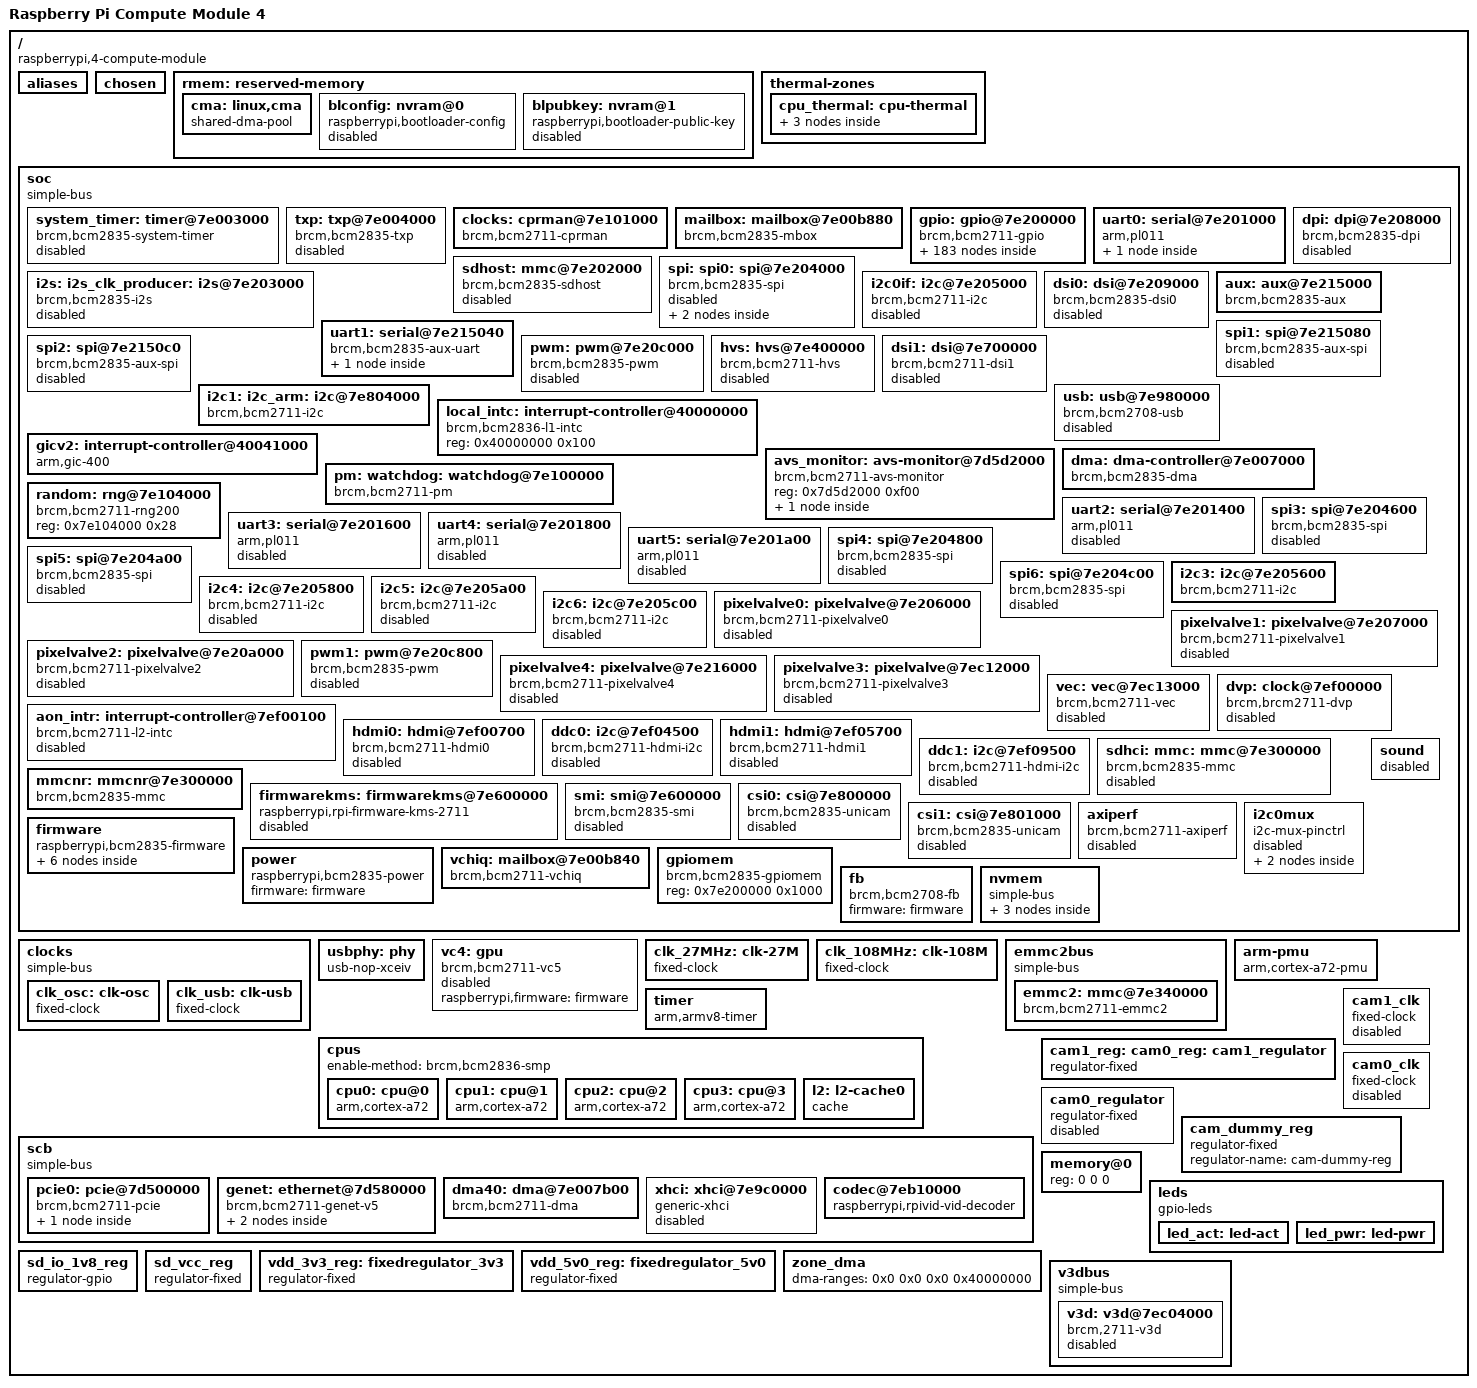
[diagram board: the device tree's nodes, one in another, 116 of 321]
/dts-v1/;

#include <dt-bindings/pinctrl/bcm2835.h>
#include <dt-bindings/clock/bcm2835.h>
#include <dt-bindings/clock/bcm2835-aux.h>
#include <dt-bindings/gpio/gpio.h>
#include <dt-bindings/interrupt-controller/irq.h>
#include <dt-bindings/soc/bcm2835-pm.h>
#include <dt-bindings/interrupt-controller/arm-gic.h>
#include <dt-bindings/power/raspberrypi-power.h>
#include <dt-bindings/reset/raspberrypi,firmware-reset.h>

/memreserve/ 0x00000000 0x00001000;

/ {
	compatible = "raspberrypi,4-compute-module", "brcm,bcm2711";
	model = "Raspberry Pi Compute Module 4";
	#address-cells = <2>;
	#size-cells = <1>;
	interrupt-parent = <&gicv2>;
	aliases: aliases {
		serial0 = &uart1;
		serial1 = &uart0;
		emmc2bus = &emmc2bus;
		ethernet0 = &genet;
		pcie0 = &pcie0;
		blconfig = &blconfig;
		blpubkey = &blpubkey;
		bluetooth = &bt;
		aux = &aux;
		sound = &sound;
		soc = &soc;
		dma = &dma;
		watchdog = &watchdog;
		random = &random;
		mailbox = &mailbox;
		gpio = &gpio;
		uart0 = &uart0;
		uart1 = &uart1;
		sdhost = &sdhost;
		mmc = &mmc;
		mmc1 = &mmcnr;
		mmc0 = &emmc2;
		i2s = &i2s;
		i2c0 = &i2c0;
		i2c1 = &i2c1;
		i2c10 = &i2c_csi_dsi;
		i2c = &i2c1;
		spi0 = &spi0;
		spi1 = &spi1;
		spi2 = &spi2;
		usb = &usb;
		leds = &leds;
		fb = &fb;
		thermal = &thermal;
		axiperf = &axiperf;
		uart2 = &uart2;
		uart3 = &uart3;
		uart4 = &uart4;
		uart5 = &uart5;
		serial2 = &uart2;
		serial3 = &uart3;
		serial4 = &uart4;
		serial5 = &uart5;
		mmc2 = &sdhost;
		i2c3 = &i2c3;
		i2c4 = &i2c4;
		i2c5 = &i2c5;
		i2c6 = &i2c6;
		i2c20 = &ddc0;
		i2c21 = &ddc1;
		spi3 = &spi3;
		spi4 = &spi4;
		spi5 = &spi5;
		spi6 = &spi6;
		i2c_arm = &i2c1;
		i2c_vc = &i2c0;
	};
	chosen: chosen {
		stdout-path = "serial0:115200n8";
		bootargs = "coherent_pool=1M 8250.nr_uarts=1 snd_bcm2835.enable_headphones=0 cgroup_disable=memory numa_policy=interleave";
	};
	rmem: reserved-memory {
		#address-cells = <2>;
		#size-cells = <1>;
		ranges;
		cma: linux,cma {
			compatible = "shared-dma-pool";
			size = <0x4000000>;
			reusable;
			linux,cma-default;
			alloc-ranges = <0x0 0x00000000 0x30000000>;
		};
		blconfig: nvram@0 {
			compatible = "raspberrypi,bootloader-config", "nvmem-rmem";
			#address-cells = <1>;
			#size-cells = <1>;
			reg = <0x0 0x0 0x0>;
			no-map;
			status = "disabled";
		};
		blpubkey: nvram@1 {
			compatible = "raspberrypi,bootloader-public-key", "nvmem-rmem";
			#address-cells = <1>;
			#size-cells = <1>;
			reg = <0x0 0x0 0x0>;
			no-map;
			status = "disabled";
		};
	};
	thermal-zones {
		cpu_thermal: cpu-thermal {
			polling-delay-passive = <0>;
			polling-delay = <1000>;
			coefficients = <(-487) 410040>;
			thermal-sensors = <&thermal>;
			thermal_trips: trips {
				cpu-crit {
					temperature = <110000>;
					hysteresis = <0>;
					type = "critical";
				};
			};
			cooling_maps: cooling-maps {
			};
		};
	};
	soc: soc {
		compatible = "simple-bus";
		#address-cells = <1>;
		#size-cells = <1>;
		ranges = <0x7e000000 0x0 0xfe000000 0x01800000>, <0x7c000000 0x0 0xfc000000 0x02000000>, <0x40000000 0x0 0xff800000 0x00800000>;
		dma-ranges = <0xc0000000 0x0 0x00000000 0x40000000>, <0x7c000000 0x0 0xfc000000 0x03800000>;
		system_timer: timer@7e003000 {
			compatible = "brcm,bcm2835-system-timer";
			reg = <0x7e003000 0x1000>;
			interrupts = <GIC_SPI 64 IRQ_TYPE_LEVEL_HIGH>, <GIC_SPI 65 IRQ_TYPE_LEVEL_HIGH>, <GIC_SPI 66 IRQ_TYPE_LEVEL_HIGH>, <GIC_SPI 67 IRQ_TYPE_LEVEL_HIGH>;
			clock-frequency = <1000000>;
			status = "disabled";
		};
		txp: txp@7e004000 {
			compatible = "brcm,bcm2835-txp";
			reg = <0x7e004000 0x20>;
			interrupts = <GIC_SPI 75 IRQ_TYPE_LEVEL_HIGH>;
			status = "disabled";
		};
		clocks: cprman@7e101000 {
			compatible = "brcm,bcm2711-cprman";
			#clock-cells = <1>;
			reg = <0x7e101000 0x2000>;
			clocks = <&clk_osc>, <&dsi0 0>, <&dsi0 1>, <&dsi0 2>, <&dsi1 0>, <&dsi1 1>, <&dsi1 2>;
			firmware = <&firmware>;
		};
		mailbox: mailbox@7e00b880 {
			compatible = "brcm,bcm2835-mbox";
			reg = <0x7e00b880 0x40>;
			interrupts = <GIC_SPI 33 IRQ_TYPE_LEVEL_HIGH>;
			#mbox-cells = <0>;
		};
		gpio: gpio@7e200000 {
			compatible = "brcm,bcm2711-gpio";
			reg = <0x7e200000 0xb4>;
			interrupts = <GIC_SPI 113 IRQ_TYPE_LEVEL_HIGH>, <GIC_SPI 114 IRQ_TYPE_LEVEL_HIGH>;
			gpio-controller;
			#gpio-cells = <2>;
			interrupt-controller;
			#interrupt-cells = <2>;
			gpio-ranges = <&gpio 0 0 58>;
			gpio-line-names = "ID_SDA", "ID_SCL", "GPIO2", "GPIO3", "GPIO4", "GPIO5", "GPIO6", "GPIO7", "GPIO8", "GPIO9", "GPIO10", "GPIO11", "GPIO12", "GPIO13", "GPIO14", "GPIO15", "GPIO16", "GPIO17", "GPIO18", "GPIO19", "GPIO20", "GPIO21", "GPIO22", "GPIO23", "GPIO24", "GPIO25", "GPIO26", "GPIO27", "RGMII_MDIO", "RGMIO_MDC", "CTS0", "RTS0", "TXD0", "RXD0", "SD1_CLK", "SD1_CMD", "SD1_DATA0", "SD1_DATA1", "SD1_DATA2", "SD1_DATA3", "PWM0_MISO", "PWM1_MOSI", "STATUS_LED_G_CLK", "SPIFLASH_CE_N", "SDA0", "SCL0", "RGMII_RXCLK", "RGMII_RXCTL", "RGMII_RXD0", "RGMII_RXD1", "RGMII_RXD2", "RGMII_RXD3", "RGMII_TXCLK", "RGMII_TXCTL", "RGMII_TXD0", "RGMII_TXD1", "RGMII_TXD2", "RGMII_TXD3";
			dpi_gpio0: dpi-gpio0 {
				brcm,pins = <0 1 2 3 4 5 6 7 8 9 10 11 12 13 14 15 16 17 18 19 20 21 22 23 24 25 26 27>;
				brcm,function = <BCM2835_FSEL_ALT2>;
			};
			emmc_gpio22: emmc-gpio22 {
				brcm,pins = <22 23 24 25 26 27>;
				brcm,function = <BCM2835_FSEL_ALT3>;
			};
			emmc_gpio34: emmc-gpio34 {
				brcm,pins = <34 35 36 37 38 39>;
				brcm,function = <BCM2835_FSEL_ALT3>;
				brcm,pull = <BCM2835_PUD_OFF BCM2835_PUD_UP BCM2835_PUD_UP BCM2835_PUD_UP BCM2835_PUD_UP BCM2835_PUD_UP>;
			};
			emmc_gpio48: emmc-gpio48 {
				brcm,pins = <48 49 50 51 52 53>;
				brcm,function = <BCM2835_FSEL_ALT3>;
			};
			gpclk0_gpio4: gpclk0-gpio4 {
				brcm,pins = <4>;
				brcm,function = <BCM2835_FSEL_ALT0>;
			};
			gpclk1_gpio5: gpclk1-gpio5 {
				brcm,pins = <5>;
				brcm,function = <BCM2835_FSEL_ALT0>;
			};
			gpclk1_gpio42: gpclk1-gpio42 {
				brcm,pins = <42>;
				brcm,function = <BCM2835_FSEL_ALT0>;
			};
			gpclk1_gpio44: gpclk1-gpio44 {
				brcm,pins = <44>;
				brcm,function = <BCM2835_FSEL_ALT0>;
			};
			gpclk2_gpio6: gpclk2-gpio6 {
				brcm,pins = <6>;
				brcm,function = <BCM2835_FSEL_ALT0>;
			};
			gpclk2_gpio43: gpclk2-gpio43 {
				brcm,pins = <43>;
				brcm,function = <BCM2835_FSEL_ALT0>;
				brcm,pull = <BCM2835_PUD_OFF>;
			};
			i2c0_gpio0: i2c0if-gpio0 {
				brcm,pins = <0 1>;
				brcm,function = <BCM2835_FSEL_ALT0>;
			};
			i2c0_gpio28: i2c0if-gpio28 {
				brcm,pins = <28 29>;
				brcm,function = <BCM2835_FSEL_ALT0>;
			};
			i2c0_gpio44: i2c0if-gpio44 {
				brcm,pins = <44 45>;
				brcm,function = <BCM2835_FSEL_ALT1>;
			};
			i2c1_gpio2: i2c1-gpio2 {
				brcm,pins = <2 3>;
				brcm,function = <BCM2835_FSEL_ALT0>;
			};
			i2c1_gpio44: i2c1-gpio44 {
				brcm,pins = <44 45>;
				brcm,function = <BCM2835_FSEL_ALT2>;
			};
			jtag_gpio22: jtag-gpio22 {
				brcm,pins = <22 23 24 25 26 27>;
				brcm,function = <BCM2835_FSEL_ALT4>;
			};
			pcm_gpio18: pcm-gpio18 {
				brcm,pins = <18 19 20 21>;
				brcm,function = <BCM2835_FSEL_ALT0>;
			};
			pcm_gpio28: pcm-gpio28 {
				brcm,pins = <28 29 30 31>;
				brcm,function = <BCM2835_FSEL_ALT2>;
			};
			sdhost_gpio48: sdhost-gpio48 {
				brcm,pins = <48 49 50 51 52 53>;
				brcm,function = <BCM2835_FSEL_ALT0>;
			};
			spi0_gpio7: spi0-gpio7 {
				brcm,pins = <7 8 9 10 11>;
				brcm,function = <BCM2835_FSEL_ALT0>;
			};
			spi0_gpio35: spi0-gpio35 {
				brcm,pins = <35 36 37 38 39>;
				brcm,function = <BCM2835_FSEL_ALT0>;
			};
			spi1_gpio16: spi1-gpio16 {
				brcm,pins = <16 17 18 19 20 21>;
				brcm,function = <BCM2835_FSEL_ALT4>;
			};
			spi2_gpio40: spi2-gpio40 {
				brcm,pins = <40 41 42 43 44 45>;
				brcm,function = <BCM2835_FSEL_ALT4>;
			};
			uart0_gpio14: uart0-gpio14 {
				brcm,pins = <14 15>;
				brcm,function = <BCM2835_FSEL_ALT0>;
			};
			uart0_ctsrts_gpio16: uart0-ctsrts-gpio16 {
				brcm,pins = <16 17>;
				brcm,function = <BCM2835_FSEL_ALT3>;
			};
			uart0_ctsrts_gpio30: uart0-ctsrts-gpio30 {
				brcm,pins = <30 31>;
				brcm,function = <BCM2835_FSEL_ALT3>;
				brcm,pull = <BCM2835_PUD_UP BCM2835_PUD_OFF>;
			};
			uart0_gpio32: uart0-gpio32 {
				brcm,pins = <32 33>;
				brcm,function = <BCM2835_FSEL_ALT3>;
				brcm,pull = <BCM2835_PUD_OFF BCM2835_PUD_UP>;
			};
			uart0_gpio36: uart0-gpio36 {
				brcm,pins = <36 37>;
				brcm,function = <BCM2835_FSEL_ALT2>;
			};
			uart0_ctsrts_gpio38: uart0-ctsrts-gpio38 {
				brcm,pins = <38 39>;
				brcm,function = <BCM2835_FSEL_ALT2>;
			};
			uart1_gpio14: uart1-gpio14 {
				brcm,pins = <14 15>;
				brcm,function = <BCM2835_FSEL_ALT5>;
			};
			uart1_ctsrts_gpio16: uart1-ctsrts-gpio16 {
				brcm,pins = <16 17>;
				brcm,function = <BCM2835_FSEL_ALT5>;
			};
			uart1_gpio32: uart1-gpio32 {
				brcm,pins = <32 33>;
				brcm,function = <BCM2835_FSEL_ALT5>;
			};
			uart1_ctsrts_gpio30: uart1-ctsrts-gpio30 {
				brcm,pins = <30 31>;
				brcm,function = <BCM2835_FSEL_ALT5>;
			};
			uart1_gpio40: uart1-gpio40 {
				brcm,pins = <40 41>;
				brcm,function = <BCM2835_FSEL_ALT5>;
			};
			uart1_ctsrts_gpio42: uart1-ctsrts-gpio42 {
				brcm,pins = <42 43>;
				brcm,function = <BCM2835_FSEL_ALT5>;
			};
			gpclk0_gpio49: gpclk0-gpio49 {
				pin-gpclk {
					pins = "gpio49";
					function = "alt1";
					bias-disable;
				};
			};
			gpclk1_gpio50: gpclk1-gpio50 {
				pin-gpclk {
					pins = "gpio50";
					function = "alt1";
					bias-disable;
				};
			};
			gpclk2_gpio51: gpclk2-gpio51 {
				pin-gpclk {
					pins = "gpio51";
					function = "alt1";
					bias-disable;
				};
			};
			i2c0_gpio46: i2c0if-gpio46 {
				pin-sda {
					function = "alt0";
					pins = "gpio46";
					bias-pull-up;
				};
				pin-scl {
					function = "alt0";
					pins = "gpio47";
					bias-disable;
				};
			};
			i2c1_gpio46: i2c1-gpio46 {
				pin-sda {
					function = "alt1";
					pins = "gpio46";
					bias-pull-up;
				};
				pin-scl {
					function = "alt1";
					pins = "gpio47";
					bias-disable;
				};
			};
			i2c3_gpio2: i2c3-gpio2 {
				pin-sda {
					function = "alt5";
					pins = "gpio2";
					bias-pull-up;
				};
				pin-scl {
					function = "alt5";
					pins = "gpio3";
					bias-disable;
				};
			};
			i2c3_gpio4: i2c3-gpio4 {
				pin-sda {
					function = "alt5";
					pins = "gpio4";
					bias-pull-up;
				};
				pin-scl {
					function = "alt5";
					pins = "gpio5";
					bias-disable;
				};
			};
			i2c4_gpio6: i2c4-gpio6 {
				pin-sda {
					function = "alt5";
					pins = "gpio6";
					bias-pull-up;
				};
				pin-scl {
					function = "alt5";
					pins = "gpio7";
					bias-disable;
				};
			};
			i2c4_gpio8: i2c4-gpio8 {
				pin-sda {
					function = "alt5";
					pins = "gpio8";
					bias-pull-up;
				};
				pin-scl {
					function = "alt5";
					pins = "gpio9";
					bias-disable;
				};
			};
			i2c5_gpio10: i2c5-gpio10 {
				pin-sda {
					function = "alt5";
					pins = "gpio10";
					bias-pull-up;
				};
				pin-scl {
					function = "alt5";
					pins = "gpio11";
					bias-disable;
				};
			};
			i2c5_gpio12: i2c5-gpio12 {
				pin-sda {
					function = "alt5";
					pins = "gpio12";
					bias-pull-up;
				};
				pin-scl {
					function = "alt5";
					pins = "gpio13";
					bias-disable;
				};
			};
			i2c6_gpio0: i2c6-gpio0 {
				pin-sda {
					function = "alt5";
					pins = "gpio0";
					bias-pull-up;
				};
				pin-scl {
					function = "alt5";
					pins = "gpio1";
					bias-disable;
				};
			};
			i2c6_gpio22: i2c6-gpio22 {
				pin-sda {
					function = "alt5";
					pins = "gpio22";
					bias-pull-up;
				};
				pin-scl {
					function = "alt5";
					pins = "gpio23";
					bias-disable;
				};
			};
			i2c_slave_gpio8: i2c-slave-gpio8 {
				pins-i2c-slave {
					pins = "gpio8", "gpio9", "gpio10", "gpio11";
					function = "alt3";
				};
			};
			jtag_gpio48: jtag-gpio48 {
				pins-jtag {
					pins = "gpio48", "gpio49", "gpio50", "gpio51", "gpio52", "gpio53";
					function = "alt4";
				};
			};
			mii_gpio28: mii-gpio28 {
				pins-mii {
					pins = "gpio28", "gpio29", "gpio30", "gpio31";
					function = "alt4";
				};
			};
			mii_gpio36: mii-gpio36 {
				pins-mii {
					pins = "gpio36", "gpio37", "gpio38", "gpio39";
					function = "alt5";
				};
			};
			pcm_gpio50: pcm-gpio50 {
				pins-pcm {
					pins = "gpio50", "gpio51", "gpio52", "gpio53";
					function = "alt2";
				};
			};
			pwm0_0_gpio12: pwm0-0-gpio12 {
				pin-pwm {
					pins = "gpio12";
					function = "alt0";
					bias-disable;
				};
			};
			pwm0_0_gpio18: pwm0-0-gpio18 {
				pin-pwm {
					pins = "gpio18";
					function = "alt5";
					bias-disable;
				};
			};
			pwm1_0_gpio40: pwm1-0-gpio40 {
				pin-pwm {
					pins = "gpio40";
					function = "alt0";
					bias-disable;
				};
			};
			pwm0_1_gpio13: pwm0-1-gpio13 {
				pin-pwm {
					pins = "gpio13";
					function = "alt0";
					bias-disable;
				};
			};
			pwm0_1_gpio19: pwm0-1-gpio19 {
				pin-pwm {
					pins = "gpio19";
					function = "alt5";
					bias-disable;
				};
			};
			pwm1_1_gpio41: pwm1-1-gpio41 {
				pin-pwm {
					pins = "gpio41";
					function = "alt0";
					bias-disable;
				};
			};
			pwm0_1_gpio45: pwm0-1-gpio45 {
				pin-pwm {
					pins = "gpio45";
					function = "alt0";
					bias-disable;
				};
			};
			pwm0_0_gpio52: pwm0-0-gpio52 {
				pin-pwm {
					pins = "gpio52";
					function = "alt1";
					bias-disable;
				};
			};
			pwm0_1_gpio53: pwm0-1-gpio53 {
				pin-pwm {
					pins = "gpio53";
					function = "alt1";
					bias-disable;
				};
			};
			rgmii_gpio35: rgmii-gpio35 {
				pin-start-stop {
					pins = "gpio35";
					function = "alt4";
				};
				pin-rx-ok {
					pins = "gpio36";
					function = "alt4";
				};
			};
			rgmii_irq_gpio34: rgmii-irq-gpio34 {
				pin-irq {
					pins = "gpio34";
					function = "alt5";
				};
			};
			rgmii_irq_gpio39: rgmii-irq-gpio39 {
				pin-irq {
					pins = "gpio39";
					function = "alt4";
				};
			};
			rgmii_mdio_gpio28: rgmii-mdio-gpio28 {
				pins-mdio {
					pins = "gpio28", "gpio29";
					function = "alt5";
				};
			};
			rgmii_mdio_gpio37: rgmii-mdio-gpio37 {
				pins-mdio {
					pins = "gpio37", "gpio38";
					function = "alt4";
				};
			};
			spi0_gpio46: spi0-gpio46 {
				pins-spi {
					pins = "gpio46", "gpio47", "gpio48", "gpio49";
					function = "alt2";
				};
			};
			spi2_gpio46: spi2-gpio46 {
				pins-spi {
					pins = "gpio46", "gpio47", "gpio48", "gpio49", "gpio50";
					function = "alt5";
				};
			};
			spi3_gpio0: spi3-gpio0 {
				pins-spi {
					pins = "gpio0", "gpio1", "gpio2", "gpio3";
					function = "alt3";
				};
			};
			spi4_gpio4: spi4-gpio4 {
				pins-spi {
					pins = "gpio4", "gpio5", "gpio6", "gpio7";
					function = "alt3";
				};
			};
			spi5_gpio12: spi5-gpio12 {
				pins-spi {
					pins = "gpio12", "gpio13", "gpio14", "gpio15";
					function = "alt3";
				};
			};
			spi6_gpio18: spi6-gpio18 {
				pins-spi {
					pins = "gpio18", "gpio19", "gpio20", "gpio21";
					function = "alt3";
				};
			};
			uart2_gpio0: uart2-gpio0 {
				pin-tx {
					pins = "gpio0";
					function = "alt4";
					bias-disable;
				};
				pin-rx {
					pins = "gpio1";
					function = "alt4";
					bias-pull-up;
				};
			};
			uart2_ctsrts_gpio2: uart2-ctsrts-gpio2 {
				pin-cts {
					pins = "gpio2";
					function = "alt4";
					bias-pull-up;
				};
				pin-rts {
					pins = "gpio3";
					function = "alt4";
					bias-disable;
				};
			};
			uart3_gpio4: uart3-gpio4 {
				pin-tx {
					pins = "gpio4";
					function = "alt4";
					bias-disable;
				};
				pin-rx {
					pins = "gpio5";
					function = "alt4";
					bias-pull-up;
				};
			};
			uart3_ctsrts_gpio6: uart3-ctsrts-gpio6 {
				pin-cts {
					pins = "gpio6";
					function = "alt4";
					bias-pull-up;
				};
				pin-rts {
					pins = "gpio7";
					function = "alt4";
					bias-disable;
				};
			};
			uart4_gpio8: uart4-gpio8 {
				pin-tx {
					pins = "gpio8";
					function = "alt4";
					bias-disable;
				};
				pin-rx {
					pins = "gpio9";
					function = "alt4";
					bias-pull-up;
				};
			};
			uart4_ctsrts_gpio10: uart4-ctsrts-gpio10 {
				pin-cts {
					pins = "gpio10";
					function = "alt4";
					bias-pull-up;
				};
				pin-rts {
					pins = "gpio11";
					function = "alt4";
					bias-disable;
				};
			};
			uart5_gpio12: uart5-gpio12 {
				pin-tx {
					pins = "gpio12";
					function = "alt4";
					bias-disable;
				};
				pin-rx {
					pins = "gpio13";
					function = "alt4";
					bias-pull-up;
				};
			};
			uart5_ctsrts_gpio14: uart5-ctsrts-gpio14 {
				pin-cts {
					pins = "gpio14";
					function = "alt4";
					bias-pull-up;
				};
				pin-rts {
					pins = "gpio15";
					function = "alt4";
					bias-disable;
				};
			};
			dpi_18bit_cpadhi_gpio0: dpi_18bit_cpadhi_gpio0 {
				brcm,pins = <0 1 2 3 4 5 6 7 8 9 12 13 14 15 16 17 20 21 22 23 24 25>;
				brcm,function = <BCM2835_FSEL_ALT2>;
				brcm,pull = <0>;
			};
			dpi_18bit_cpadhi_gpio2: dpi_18bit_cpadhi_gpio2 {
				brcm,pins = <2 3 4 5 6 7 8 9 12 13 14 15 16 17 20 21 22 23 24 25>;
				brcm,function = <BCM2835_FSEL_ALT2>;
			};
			dpi_18bit_gpio0: dpi_18bit_gpio0 {
				brcm,pins = <0 1 2 3 4 5 6 7 8 9 10 11 12 13 14 15 16 17 18 19 20 21>;
				brcm,function = <BCM2835_FSEL_ALT2>;
			};
			dpi_18bit_gpio2: dpi_18bit_gpio2 {
				brcm,pins = <2 3 4 5 6 7 8 9 10 11 12 13 14 15 16 17 18 19 20 21>;
				brcm,function = <BCM2835_FSEL_ALT2>;
			};
			dpi_16bit_gpio0: dpi_16bit_gpio0 {
				brcm,pins = <0 1 2 3 4 5 6 7 8 9 10 11 12 13 14 15 16 17 18 19>;
				brcm,function = <BCM2835_FSEL_ALT2>;
			};
			dpi_16bit_gpio2: dpi_16bit_gpio2 {
				brcm,pins = <2 3 4 5 6 7 8 9 10 11 12 13 14 15 16 17 18 19>;
				brcm,function = <BCM2835_FSEL_ALT2>;
			};
			dpi_16bit_cpadhi_gpio0: dpi_16bit_cpadhi_gpio0 {
				brcm,pins = <0 1 2 3 4 5 6 7 8 12 13 14 15 16 17 20 21 22 23 24>;
				brcm,function = <BCM2835_FSEL_ALT2>;
			};
			dpi_16bit_cpadhi_gpio2: dpi_16bit_cpadhi_gpio2 {
				brcm,pins = <2 3 4 5 6 7 8 12 13 14 15 16 17 20 21 22 23 24>;
				brcm,function = <BCM2835_FSEL_ALT2>;
			};
			gpioout: gpioout {
				brcm,pins = <6>;
				brcm,function = <BCM2835_FSEL_GPIO_OUT>;
			};
			alt0: alt0 {
				brcm,pins = <4 5 7 8 9 10 11>;
				brcm,function = <BCM2835_FSEL_ALT0>;
			};
			spi0_pins: spi0_pins {
				brcm,pins = <9 10 11>;
				brcm,function = <BCM2835_FSEL_ALT0>;
			};
			spi0_cs_pins: spi0_cs_pins {
				brcm,pins = <8 7>;
				brcm,function = <BCM2835_FSEL_GPIO_OUT>;
			};
			spi3_pins: spi3_pins {
				brcm,pins = <1 2 3>;
				brcm,function = <BCM2835_FSEL_ALT3>;
			};
			spi3_cs_pins: spi3_cs_pins {
				brcm,pins = <0 24>;
				brcm,function = <BCM2835_FSEL_GPIO_OUT>;
			};
			spi4_pins: spi4_pins {
				brcm,pins = <5 6 7>;
				brcm,function = <BCM2835_FSEL_ALT3>;
			};
			spi4_cs_pins: spi4_cs_pins {
				brcm,pins = <4 25>;
				brcm,function = <BCM2835_FSEL_GPIO_OUT>;
			};
			spi5_pins: spi5_pins {
				brcm,pins = <13 14 15>;
				brcm,function = <BCM2835_FSEL_ALT3>;
			};
			spi5_cs_pins: spi5_cs_pins {
				brcm,pins = <12 26>;
				brcm,function = <BCM2835_FSEL_GPIO_OUT>;
			};
			spi6_pins: spi6_pins {
				brcm,pins = <19 20 21>;
				brcm,function = <BCM2835_FSEL_ALT3>;
			};
			spi6_cs_pins: spi6_cs_pins {
				brcm,pins = <18 27>;
				brcm,function = <BCM2835_FSEL_GPIO_OUT>;
			};
			i2c0_pins: i2c0 {
				brcm,pins = <0 1>;
				brcm,function = <BCM2835_FSEL_ALT0>;
				brcm,pull = <BCM2835_PUD_UP>;
			};
			i2c1_pins: i2c1 {
				brcm,pins = <2 3>;
				brcm,function = <BCM2835_FSEL_ALT0>;
				brcm,pull = <BCM2835_PUD_UP>;
			};
			i2c3_pins: i2c3 {
				brcm,pins = <4 5>;
				brcm,function = <BCM2835_FSEL_ALT5>;
				brcm,pull = <BCM2835_PUD_UP>;
			};
			i2c4_pins: i2c4 {
				brcm,pins = <8 9>;
				brcm,function = <BCM2835_FSEL_ALT5>;
				brcm,pull = <BCM2835_PUD_UP>;
			};
			i2c5_pins: i2c5 {
				brcm,pins = <12 13>;
				brcm,function = <BCM2835_FSEL_ALT5>;
				brcm,pull = <BCM2835_PUD_UP>;
			};
			i2c6_pins: i2c6 {
				brcm,pins = <22 23>;
				brcm,function = <BCM2835_FSEL_ALT5>;
				brcm,pull = <BCM2835_PUD_UP>;
			};
			i2s_pins: i2s {
				brcm,pins = <18 19 20 21>;
				brcm,function = <BCM2835_FSEL_ALT0>;
			};
			sdio_pins: sdio_pins {
				brcm,pins = <34 35 36 37 38 39>;
				brcm,function = <BCM2835_FSEL_ALT3>;
				brcm,pull = <0 2 2 2 2 2>;
			};
			uart2_pins: uart2_pins {
				brcm,pins = <0 1>;
				brcm,function = <BCM2835_FSEL_ALT4>;
				brcm,pull = <0 2>;
			};
			uart3_pins: uart3_pins {
				brcm,pins = <4 5>;
				brcm,function = <BCM2835_FSEL_ALT4>;
				brcm,pull = <0 2>;
			};
			uart4_pins: uart4_pins {
				brcm,pins = <8 9>;
				brcm,function = <BCM2835_FSEL_ALT4>;
				brcm,pull = <0 2>;
			};
			uart5_pins: uart5_pins {
				brcm,pins = <12 13>;
				brcm,function = <BCM2835_FSEL_ALT4>;
				brcm,pull = <0 2>;
			};
			bt_pins: bt_pins {
				brcm,pins = "-";
				brcm,function = <0>;
				brcm,pull = <2>;
			};
			uart0_pins: uart0_pins {
				brcm,pins = <32 33>;
				brcm,function = <BCM2835_FSEL_ALT3>;
				brcm,pull = <0 2>;
			};
			uart1_pins: uart1_pins {
				brcm,pins;
				brcm,function;
				brcm,pull;
			};
			uart1_bt_pins: uart1_bt_pins {
				brcm,pins = <32 33 30 31>;
				brcm,function = <BCM2835_FSEL_ALT5>;
				brcm,pull = <0 2 2 0>;
			};
			audio_pins: audio_pins {
				brcm,pins = <>;
				brcm,function = <>;
			};
		};
		uart0: serial@7e201000 {
			compatible = "arm,pl011", "arm,primecell";
			reg = <0x7e201000 0x200>;
			interrupts = <GIC_SPI 121 IRQ_TYPE_LEVEL_HIGH>;
			clocks = <&clocks BCM2835_CLOCK_UART>, <&clocks BCM2835_CLOCK_VPU>;
			clock-names = "uartclk", "apb_pclk";
			arm,primecell-periphid = <0x00241011>;
			status = "okay";
			cts-event-workaround;
			pinctrl-names = "default";
			pinctrl-0 = <&uart0_pins &bt_pins>;
			uart-has-rtscts;
			skip-init;
			bt: bluetooth {
				compatible = "brcm,bcm43438-bt";
				max-speed = <3000000>;
				shutdown-gpios = <&expgpio 0 GPIO_ACTIVE_HIGH>;
				local-bd-address = [00 00 00 00 00 00];
				fallback-bd-address;
				status = "okay";
			};
		};
		sdhost: mmc@7e202000 {
			compatible = "brcm,bcm2835-sdhost";
			reg = <0x7e202000 0x100>;
			interrupts = <GIC_SPI 120 IRQ_TYPE_LEVEL_HIGH>;
			clocks = <&clocks BCM2835_CLOCK_VPU>;
			status = "disabled";
			dmas = <&dma (13|(1<<29))>;
			dma-names = "rx-tx";
			bus-width = <4>;
			brcm,overclock-50 = <0>;
			brcm,pio-limit = <1>;
			firmware = <&firmware>;
		};
		i2s: i2s_clk_producer: i2s_clk_consumer: i2s@7e203000 {
			compatible = "brcm,bcm2835-i2s";
			reg = <0x7e203000 0x24>;
			clocks = <&clocks BCM2835_CLOCK_PCM>;
			status = "disabled";
			#sound-dai-cells = <0>;
			dmas = <&dma 2>, <&dma 3>;
			dma-names = "tx", "rx";
			pinctrl-names = "default";
			pinctrl-0 = <&i2s_pins>;
		};
		spi: spi0: spi@7e204000 {
			compatible = "brcm,bcm2835-spi";
			reg = <0x7e204000 0x200>;
			interrupts = <GIC_SPI 118 IRQ_TYPE_LEVEL_HIGH>;
			clocks = <&clocks BCM2835_CLOCK_VPU>;
			#address-cells = <1>;
			#size-cells = <0>;
			status = "disabled";
			dmas = <&dma 6>, <&dma 7>;
			dma-names = "tx", "rx";
			pinctrl-names = "default";
			pinctrl-0 = <&spi0_pins &spi0_cs_pins>;
			cs-gpios = <&gpio 8 1>, <&gpio 7 1>;
			spidev0: spidev@0 {
				compatible = "spidev";
				reg = <0>;
				#address-cells = <1>;
				#size-cells = <0>;
				spi-max-frequency = <125000000>;
			};
			spidev1: spidev@1 {
				compatible = "spidev";
				reg = <1>;
				#address-cells = <1>;
				#size-cells = <0>;
				spi-max-frequency = <125000000>;
			};
		};
		i2c0if: i2c@7e205000 {
			compatible = "brcm,bcm2711-i2c", "brcm,bcm2835-i2c";
			reg = <0x7e205000 0x200>;
			interrupts = <GIC_SPI 117 IRQ_TYPE_LEVEL_HIGH>;
			clocks = <&clocks BCM2835_CLOCK_VPU>;
			#address-cells = <1>;
			#size-cells = <0>;
			status = "disabled";
			clock-frequency = <100000>;
		};
		dpi: dpi@7e208000 {
			compatible = "brcm,bcm2835-dpi";
			reg = <0x7e208000 0x8c>;
			clocks = <&clocks BCM2835_CLOCK_VPU>, <&clocks BCM2835_CLOCK_DPI>;
			clock-names = "core", "pixel";
			status = "disabled";
		};
		dsi0: dsi@7e209000 {
			compatible = "brcm,bcm2835-dsi0";
			reg = <0x7e209000 0x78>;
			interrupts = <GIC_SPI 100 IRQ_TYPE_LEVEL_HIGH>;
			#address-cells = <1>;
			#size-cells = <0>;
			#clock-cells = <1>;
			clocks = <&clocks BCM2835_PLLD_DSI0>, <&clocks BCM2835_CLOCK_DSI0E>, <&clocks BCM2835_CLOCK_DSI0P>;
			clock-names = "phy", "escape", "pixel";
			clock-output-names = "dsi0_byte", "dsi0_ddr2", "dsi0_ddr";
			status = "disabled";
			power-domains = <&power RPI_POWER_DOMAIN_DSI0>;
		};
		aux: aux@7e215000 {
			compatible = "brcm,bcm2835-aux";
			#clock-cells = <1>;
			reg = <0x7e215000 0x8>;
			clocks = <&clocks BCM2835_CLOCK_VPU>;
		};
		uart1: serial@7e215040 {
			compatible = "brcm,bcm2835-aux-uart";
			reg = <0x7e215040 0x40>;
			interrupts = <GIC_SPI 93 IRQ_TYPE_LEVEL_HIGH>;
			clocks = <&aux BCM2835_AUX_CLOCK_UART>;
			status = "okay";
			pinctrl-names = "default";
			pinctrl-0 = <&uart1_pins>;
			skip-init;
			minibt: bluetooth {
				compatible = "brcm,bcm43438-bt";
				max-speed = <230400>;
				shutdown-gpios = <&expgpio 0 GPIO_ACTIVE_HIGH>;
				local-bd-address = [00 00 00 00 00 00];
				fallback-bd-address;
				status = "disabled";
			};
		};
		spi1: spi@7e215080 {
			compatible = "brcm,bcm2835-aux-spi";
			reg = <0x7e215080 0x40>;
			interrupts = <GIC_SPI 93 IRQ_TYPE_LEVEL_HIGH>;
			clocks = <&aux BCM2835_AUX_CLOCK_SPI1>;
			#address-cells = <1>;
			#size-cells = <0>;
			status = "disabled";
		};
		spi2: spi@7e2150c0 {
			compatible = "brcm,bcm2835-aux-spi";
			reg = <0x7e2150c0 0x40>;
			interrupts = <GIC_SPI 93 IRQ_TYPE_LEVEL_HIGH>;
			clocks = <&aux BCM2835_AUX_CLOCK_SPI2>;
			#address-cells = <1>;
			#size-cells = <0>;
			status = "disabled";
		};
		pwm: pwm@7e20c000 {
			compatible = "brcm,bcm2835-pwm";
			reg = <0x7e20c000 0x28>;
			clocks = <&clocks BCM2835_CLOCK_PWM>;
			assigned-clocks = <&clocks BCM2835_CLOCK_PWM>;
			assigned-clock-rates = <50000000>;
			#pwm-cells = <3>;
			status = "disabled";
		};
		hvs: hvs@7e400000 {
			compatible = "brcm,bcm2711-hvs";
			reg = <0x7e400000 0x8000>;
			interrupts = <GIC_SPI 97 IRQ_TYPE_LEVEL_HIGH>;
			status = "disabled";
			clocks = <&firmware_clocks 4>;
		};
		dsi1: dsi@7e700000 {
			compatible = "brcm,bcm2711-dsi1";
			reg = <0x7e700000 0x8c>;
			interrupts = <GIC_SPI 108 IRQ_TYPE_LEVEL_HIGH>;
			#address-cells = <1>;
			#size-cells = <0>;
			#clock-cells = <1>;
			clocks = <&clocks BCM2835_PLLD_DSI1>, <&clocks BCM2835_CLOCK_DSI1E>, <&clocks BCM2835_CLOCK_DSI1P>;
			clock-names = "phy", "escape", "pixel";
			clock-output-names = "dsi1_byte", "dsi1_ddr2", "dsi1_ddr";
			status = "disabled";
			power-domains = <&power RPI_POWER_DOMAIN_DSI1>;
		};
		i2c1: i2c_arm: i2c@7e804000 {
			compatible = "brcm,bcm2711-i2c", "brcm,bcm2835-i2c";
			reg = <0x7e804000 0x1000>;
			interrupts = <GIC_SPI 117 IRQ_TYPE_LEVEL_HIGH>;
			clocks = <&clocks BCM2835_CLOCK_VPU>;
			#address-cells = <1>;
			#size-cells = <0>;
			status = "okay";
			pinctrl-names = "default";
			pinctrl-0 = <&i2c1_pins>;
			clock-frequency = <100000>;
		};
		usb: usb@7e980000 {
			compatible = "brcm,bcm2708-usb";
			reg = <0x7e980000 0x10000>, <0x7e00b200 0x200>;
			interrupts = <GIC_SPI 73 IRQ_TYPE_LEVEL_HIGH>, <GIC_SPI 40 IRQ_TYPE_LEVEL_HIGH>;
			#address-cells = <1>;
			#size-cells = <0>;
			clocks = <&clk_usb>;
			clock-names = "otg";
			phys = <&usbphy>;
			phy-names = "usb2-phy";
			interrupt-names = "usb", "soft";
			power-domains = <&power RPI_POWER_DOMAIN_USB>;
			status = "disabled";
		};
		local_intc: interrupt-controller@40000000 {
			compatible = "brcm,bcm2836-l1-intc";
			reg = <0x40000000 0x100>;
		};
		gicv2: interrupt-controller@40041000 {
			interrupt-controller;
			#interrupt-cells = <3>;
			compatible = "arm,gic-400";
			reg = <0x40041000 0x1000>, <0x40042000 0x2000>, <0x40044000 0x2000>, <0x40046000 0x2000>;
			interrupts = <GIC_PPI 9 (GIC_CPU_MASK_SIMPLE(4) |IRQ_TYPE_LEVEL_HIGH)>;
		};
		avs_monitor: avs-monitor@7d5d2000 {
			compatible = "brcm,bcm2711-avs-monitor", "syscon", "simple-mfd";
			reg = <0x7d5d2000 0xf00>;
			thermal: thermal {
				compatible = "brcm,bcm2711-thermal";
				#thermal-sensor-cells = <0>;
			};
		};
		dma: dma-controller@7e007000 {
			compatible = "brcm,bcm2835-dma";
			reg = <0x7e007000 0xb00>;
			interrupts = <GIC_SPI 80 IRQ_TYPE_LEVEL_HIGH>, <GIC_SPI 81 IRQ_TYPE_LEVEL_HIGH>, <GIC_SPI 82 IRQ_TYPE_LEVEL_HIGH>, <GIC_SPI 83 IRQ_TYPE_LEVEL_HIGH>, <GIC_SPI 84 IRQ_TYPE_LEVEL_HIGH>, <GIC_SPI 85 IRQ_TYPE_LEVEL_HIGH>, <GIC_SPI 86 IRQ_TYPE_LEVEL_HIGH>, <GIC_SPI 87 IRQ_TYPE_LEVEL_HIGH>, <GIC_SPI 87 IRQ_TYPE_LEVEL_HIGH>, <GIC_SPI 88 IRQ_TYPE_LEVEL_HIGH>, <GIC_SPI 88 IRQ_TYPE_LEVEL_HIGH>;
			interrupt-names = "dma0", "dma1", "dma2", "dma3", "dma4", "dma5", "dma6", "dma7", "dma8", "dma9", "dma10";
			#dma-cells = <1>;
			brcm,dma-channel-mask = <0x07f5>;
		};
		pm: watchdog: watchdog@7e100000 {
			compatible = "brcm,bcm2711-pm", "brcm,bcm2835-pm-wdt";
			#power-domain-cells = <1>;
			#reset-cells = <1>;
			reg = <0x7e100000 0x114>, <0x7e00a000 0x24>, <0x7ec11000 0x20>;
			reg-names = "pm", "asb", "rpivid_asb";
			clocks = <&clocks BCM2835_CLOCK_V3D>, <&clocks BCM2835_CLOCK_PERI_IMAGE>, <&clocks BCM2835_CLOCK_H264>, <&clocks BCM2835_CLOCK_ISP>;
			clock-names = "v3d", "peri_image", "h264", "isp";
			system-power-controller;
		};
		random: rng@7e104000 {
			compatible = "brcm,bcm2711-rng200";
			reg = <0x7e104000 0x28>;
			status = "okay";
		};
		uart2: serial@7e201400 {
			compatible = "arm,pl011", "arm,primecell";
			reg = <0x7e201400 0x200>;
			interrupts = <GIC_SPI 121 IRQ_TYPE_LEVEL_HIGH>;
			clocks = <&clocks BCM2835_CLOCK_UART>, <&clocks BCM2835_CLOCK_VPU>;
			clock-names = "uartclk", "apb_pclk";
			arm,primecell-periphid = <0x00241011>;
			status = "disabled";
			pinctrl-0 = <&uart2_pins>;
			pinctrl-names = "default";
		};
		uart3: serial@7e201600 {
			compatible = "arm,pl011", "arm,primecell";
			reg = <0x7e201600 0x200>;
			interrupts = <GIC_SPI 121 IRQ_TYPE_LEVEL_HIGH>;
			clocks = <&clocks BCM2835_CLOCK_UART>, <&clocks BCM2835_CLOCK_VPU>;
			clock-names = "uartclk", "apb_pclk";
			arm,primecell-periphid = <0x00241011>;
			status = "disabled";
			pinctrl-0 = <&uart3_pins>;
			pinctrl-names = "default";
		};
		uart4: serial@7e201800 {
			compatible = "arm,pl011", "arm,primecell";
			reg = <0x7e201800 0x200>;
			interrupts = <GIC_SPI 121 IRQ_TYPE_LEVEL_HIGH>;
			clocks = <&clocks BCM2835_CLOCK_UART>, <&clocks BCM2835_CLOCK_VPU>;
			clock-names = "uartclk", "apb_pclk";
			arm,primecell-periphid = <0x00241011>;
			status = "disabled";
			pinctrl-0 = <&uart4_pins>;
			pinctrl-names = "default";
		};
		uart5: serial@7e201a00 {
			compatible = "arm,pl011", "arm,primecell";
			reg = <0x7e201a00 0x200>;
			interrupts = <GIC_SPI 121 IRQ_TYPE_LEVEL_HIGH>;
			clocks = <&clocks BCM2835_CLOCK_UART>, <&clocks BCM2835_CLOCK_VPU>;
			clock-names = "uartclk", "apb_pclk";
			arm,primecell-periphid = <0x00241011>;
			status = "disabled";
			pinctrl-0 = <&uart5_pins>;
			pinctrl-names = "default";
		};
		spi3: spi@7e204600 {
			compatible = "brcm,bcm2835-spi";
			reg = <0x7e204600 0x0200>;
			interrupts = <GIC_SPI 118 IRQ_TYPE_LEVEL_HIGH>;
			clocks = <&clocks BCM2835_CLOCK_VPU>;
			#address-cells = <1>;
			#size-cells = <0>;
			status = "disabled";
			pinctrl-0 = <&spi3_pins &spi3_cs_pins>;
			pinctrl-names = "default";
		};
		spi4: spi@7e204800 {
			compatible = "brcm,bcm2835-spi";
			reg = <0x7e204800 0x0200>;
			interrupts = <GIC_SPI 118 IRQ_TYPE_LEVEL_HIGH>;
			clocks = <&clocks BCM2835_CLOCK_VPU>;
			#address-cells = <1>;
			#size-cells = <0>;
			status = "disabled";
			pinctrl-0 = <&spi4_pins &spi4_cs_pins>;
			pinctrl-names = "default";
		};
		spi5: spi@7e204a00 {
			compatible = "brcm,bcm2835-spi";
			reg = <0x7e204a00 0x0200>;
			interrupts = <GIC_SPI 118 IRQ_TYPE_LEVEL_HIGH>;
			clocks = <&clocks BCM2835_CLOCK_VPU>;
			#address-cells = <1>;
			#size-cells = <0>;
			status = "disabled";
			pinctrl-0 = <&spi5_pins &spi5_cs_pins>;
			pinctrl-names = "default";
		};
		spi6: spi@7e204c00 {
			compatible = "brcm,bcm2835-spi";
			reg = <0x7e204c00 0x0200>;
			interrupts = <GIC_SPI 118 IRQ_TYPE_LEVEL_HIGH>;
			clocks = <&clocks BCM2835_CLOCK_VPU>;
			#address-cells = <1>;
			#size-cells = <0>;
			status = "disabled";
			pinctrl-0 = <&spi6_pins &spi6_cs_pins>;
			pinctrl-names = "default";
		};
		i2c3: i2c@7e205600 {
			compatible = "brcm,bcm2711-i2c", "brcm,bcm2835-i2c";
			reg = <0x7e205600 0x200>;
			interrupts = <GIC_SPI 117 IRQ_TYPE_LEVEL_HIGH>;
			clocks = <&clocks BCM2835_CLOCK_VPU>;
			#address-cells = <1>;
			#size-cells = <0>;
			status = "okay";
			pinctrl-0 = <&i2c3_pins>;
			pinctrl-names = "default";
			clock-frequency = <100000>;
		};
		i2c4: i2c@7e205800 {
			compatible = "brcm,bcm2711-i2c", "brcm,bcm2835-i2c";
			reg = <0x7e205800 0x200>;
			interrupts = <GIC_SPI 117 IRQ_TYPE_LEVEL_HIGH>;
			clocks = <&clocks BCM2835_CLOCK_VPU>;
			#address-cells = <1>;
			#size-cells = <0>;
			status = "disabled";
			pinctrl-0 = <&i2c4_pins>;
			pinctrl-names = "default";
		};
		i2c5: i2c@7e205a00 {
			compatible = "brcm,bcm2711-i2c", "brcm,bcm2835-i2c";
			reg = <0x7e205a00 0x200>;
			interrupts = <GIC_SPI 117 IRQ_TYPE_LEVEL_HIGH>;
			clocks = <&clocks BCM2835_CLOCK_VPU>;
			#address-cells = <1>;
			#size-cells = <0>;
			status = "disabled";
			pinctrl-0 = <&i2c5_pins>;
			pinctrl-names = "default";
		};
		i2c6: i2c@7e205c00 {
			compatible = "brcm,bcm2711-i2c", "brcm,bcm2835-i2c";
			reg = <0x7e205c00 0x200>;
			interrupts = <GIC_SPI 117 IRQ_TYPE_LEVEL_HIGH>;
			clocks = <&clocks BCM2835_CLOCK_VPU>;
			#address-cells = <1>;
			#size-cells = <0>;
			status = "disabled";
			pinctrl-0 = <&i2c6_pins>;
			pinctrl-names = "default";
		};
		pixelvalve0: pixelvalve@7e206000 {
			compatible = "brcm,bcm2711-pixelvalve0";
			reg = <0x7e206000 0x100>;
			interrupts = <GIC_SPI 109 IRQ_TYPE_LEVEL_HIGH>;
			status = "disabled";
		};
		pixelvalve1: pixelvalve@7e207000 {
			compatible = "brcm,bcm2711-pixelvalve1";
			reg = <0x7e207000 0x100>;
			interrupts = <GIC_SPI 110 IRQ_TYPE_LEVEL_HIGH>;
			status = "disabled";
		};
		pixelvalve2: pixelvalve@7e20a000 {
			compatible = "brcm,bcm2711-pixelvalve2";
			reg = <0x7e20a000 0x100>;
			interrupts = <GIC_SPI 101 IRQ_TYPE_LEVEL_HIGH>;
			status = "disabled";
		};
		pwm1: pwm@7e20c800 {
			compatible = "brcm,bcm2835-pwm";
			reg = <0x7e20c800 0x28>;
			clocks = <&clocks BCM2835_CLOCK_PWM>;
			assigned-clocks = <&clocks BCM2835_CLOCK_PWM>;
			assigned-clock-rates = <50000000>;
			#pwm-cells = <3>;
			status = "disabled";
			pinctrl-names = "default";
			pinctrl-0 = <&pwm1_0_gpio40 &pwm1_1_gpio41>;
		};
		pixelvalve4: pixelvalve@7e216000 {
			compatible = "brcm,bcm2711-pixelvalve4";
			reg = <0x7e216000 0x100>;
			interrupts = <GIC_SPI 110 IRQ_TYPE_LEVEL_HIGH>;
			status = "disabled";
		};
		pixelvalve3: pixelvalve@7ec12000 {
			compatible = "brcm,bcm2711-pixelvalve3";
			reg = <0x7ec12000 0x100>;
			interrupts = <GIC_SPI 106 IRQ_TYPE_LEVEL_HIGH>;
			status = "disabled";
		};
		vec: vec@7ec13000 {
			compatible = "brcm,bcm2711-vec";
			reg = <0x7ec13000 0x1000>;
			clocks = <&firmware_clocks 15>;
			interrupts = <GIC_SPI 123 IRQ_TYPE_LEVEL_HIGH>;
			status = "disabled";
			power-domains = <&power RPI_POWER_DOMAIN_VEC>;
		};
		dvp: clock@7ef00000 {
			compatible = "brcm,brcm2711-dvp";
			reg = <0x7ef00000 0x10>;
			clocks = <&clk_108MHz>;
			#clock-cells = <1>;
			#reset-cells = <1>;
			status = "disabled";
		};
		aon_intr: interrupt-controller@7ef00100 {
			compatible = "brcm,bcm2711-l2-intc", "brcm,l2-intc";
			reg = <0x7ef00100 0x30>;
			interrupts = <GIC_SPI 96 IRQ_TYPE_EDGE_RISING>;
			interrupt-controller;
			#interrupt-cells = <1>;
			status = "disabled";
		};
		hdmi0: hdmi@7ef00700 {
			compatible = "brcm,bcm2711-hdmi0";
			reg = <0x7ef00700 0x300>, <0x7ef00300 0x200>, <0x7ef00f00 0x80>, <0x7ef00f80 0x80>, <0x7ef01b00 0x200>, <0x7ef01f00 0x400>, <0x7ef00200 0x80>, <0x7ef04300 0x100>, <0x7ef20000 0x100>, <0x7ef00100 0x30>;
			reg-names = "hdmi", "dvp", "phy", "rm", "packet", "metadata", "csc", "cec", "hd", "intr2";
			clock-names = "hdmi", "bvb", "audio", "cec";
			resets = <&dvp 0>;
			interrupt-parent = <&aon_intr>;
			interrupts = <0>, <1>, <2>, <3>, <4>, <5>;
			interrupt-names = "cec-tx", "cec-rx", "cec-low", "wakeup", "hpd-connected", "hpd-removed";
			ddc = <&ddc0>;
			dmas = <&dma40 (10|(1<<30)|(1<<24)|(10<<16)|(15<<20))>;
			dma-names = "audio-rx";
			status = "disabled";
			clocks = <&firmware_clocks 13>, <&firmware_clocks 14>, <&dvp 0>, <&clk_27MHz>;
			wifi-2.4ghz-coexistence;
		};
		ddc0: i2c@7ef04500 {
			compatible = "brcm,bcm2711-hdmi-i2c";
			reg = <0x7ef04500 0x100>, <0x7ef00b00 0x300>;
			reg-names = "bsc", "auto-i2c";
			clock-frequency = <97500>;
			status = "disabled";
		};
		hdmi1: hdmi@7ef05700 {
			compatible = "brcm,bcm2711-hdmi1";
			reg = <0x7ef05700 0x300>, <0x7ef05300 0x200>, <0x7ef05f00 0x80>, <0x7ef05f80 0x80>, <0x7ef06b00 0x200>, <0x7ef06f00 0x400>, <0x7ef00280 0x80>, <0x7ef09300 0x100>, <0x7ef20000 0x100>, <0x7ef00100 0x30>;
			reg-names = "hdmi", "dvp", "phy", "rm", "packet", "metadata", "csc", "cec", "hd", "intr2";
			ddc = <&ddc1>;
			clock-names = "hdmi", "bvb", "audio", "cec";
			resets = <&dvp 1>;
			interrupt-parent = <&aon_intr>;
			interrupts = <8>, <7>, <6>, <9>, <10>, <11>;
			interrupt-names = "cec-tx", "cec-rx", "cec-low", "wakeup", "hpd-connected", "hpd-removed";
			dmas = <&dma40 (17|(1<<30)|(1<<24)|(10<<16)|(15<<20))>;
			dma-names = "audio-rx";
			status = "disabled";
			clocks = <&firmware_clocks 13>, <&firmware_clocks 14>, <&dvp 1>, <&clk_27MHz>;
			wifi-2.4ghz-coexistence;
		};
		ddc1: i2c@7ef09500 {
			compatible = "brcm,bcm2711-hdmi-i2c";
			reg = <0x7ef09500 0x100>, <0x7ef05b00 0x300>;
			reg-names = "bsc", "auto-i2c";
			clock-frequency = <97500>;
			status = "disabled";
		};
		sdhci: mmc: mmc@7e300000 {
			compatible = "brcm,bcm2835-mmc", "brcm,bcm2835-sdhci";
			reg = <0x7e300000 0x100>;
			interrupts = <GIC_SPI 126 IRQ_TYPE_LEVEL_HIGH>;
			clocks = <&clocks BCM2835_CLOCK_EMMC>;
			dmas = <&dma 11>;
			dma-names = "rx-tx";
			brcm,overclock-50 = <0>;
			status = "disabled";
			pinctrl-names = "default";
			pinctrl-0 = <&emmc_gpio48>;
			bus-width = <4>;
		};
		mmcnr: mmcnr@7e300000 {
			compatible = "brcm,bcm2835-mmc", "brcm,bcm2835-sdhci";
			reg = <0x7e300000 0x100>;
			interrupts = <GIC_SPI 126 IRQ_TYPE_LEVEL_HIGH>;
			clocks = <&clocks BCM2835_CLOCK_EMMC>;
			dmas = <&dma 11>;
			dma-names = "rx-tx";
			brcm,overclock-50 = <0>;
			non-removable;
			status = "okay";
			pinctrl-names = "default";
			pinctrl-0 = <&sdio_pins>;
			bus-width = <4>;
		};
		firmwarekms: firmwarekms@7e600000 {
			compatible = "raspberrypi,rpi-firmware-kms-2711";
			reg = <0x7e600000 0x100>;
			interrupts = <GIC_SPI 112 IRQ_TYPE_LEVEL_HIGH>;
			brcm,firmware = <&firmware>;
			status = "disabled";
		};
		smi: smi@7e600000 {
			compatible = "brcm,bcm2835-smi";
			reg = <0x7e600000 0x100>;
			interrupts = <GIC_SPI 112 IRQ_TYPE_LEVEL_HIGH>;
			clocks = <&clocks BCM2835_CLOCK_SMI>;
			assigned-clocks = <&clocks BCM2835_CLOCK_SMI>;
			assigned-clock-rates = <125000000>;
			dmas = <&dma 4>;
			dma-names = "rx-tx";
			status = "disabled";
		};
		csi0: csi@7e800000 {
			compatible = "brcm,bcm2835-unicam";
			reg = <0x7e800000 0x800>, <0x7e802000 0x4>;
			interrupts = <GIC_SPI 102 IRQ_TYPE_LEVEL_HIGH>;
			clocks = <&clocks BCM2835_CLOCK_CAM0>, <&firmware_clocks 4>;
			clock-names = "lp", "vpu";
			power-domains = <&power RPI_POWER_DOMAIN_UNICAM0>;
			#address-cells = <1>;
			#size-cells = <0>;
			#clock-cells = <1>;
			status = "disabled";
			brcm,num-data-lanes = <2>;
		};
		csi1: csi@7e801000 {
			compatible = "brcm,bcm2835-unicam";
			reg = <0x7e801000 0x800>, <0x7e802004 0x4>;
			interrupts = <GIC_SPI 103 IRQ_TYPE_LEVEL_HIGH>;
			clocks = <&clocks BCM2835_CLOCK_CAM1>, <&firmware_clocks 4>;
			clock-names = "lp", "vpu";
			power-domains = <&power RPI_POWER_DOMAIN_UNICAM1>;
			#address-cells = <1>;
			#size-cells = <0>;
			#clock-cells = <1>;
			status = "disabled";
			brcm,num-data-lanes = <4>;
		};
		axiperf: axiperf {
			compatible = "brcm,bcm2711-axiperf";
			reg = <0x7e009800 0x100>, <0x7ee08000 0x100>;
			firmware = <&firmware>;
			status = "disabled";
		};
		i2c0mux: i2c0mux {
			compatible = "i2c-mux-pinctrl";
			#address-cells = <1>;
			#size-cells = <0>;
			i2c-parent = <&i2c0if>;
			status = "disabled";
			pinctrl-names = "i2c0", "i2c_csi_dsi";
			pinctrl-0 = <&i2c0_gpio0>;
			pinctrl-1 = <&i2c0_gpio44>;
			i2c0: i2c_vc: i2c_csi_dsi0: i2c@0 {
				reg = <0>;
				#address-cells = <1>;
				#size-cells = <0>;
			};
			i2c_csi_dsi: i2c@1 {
				reg = <1>;
				#address-cells = <1>;
				#size-cells = <0>;
			};
		};
		firmware: firmware {
			compatible = "raspberrypi,bcm2835-firmware", "simple-mfd";
			#address-cells = <1>;
			#size-cells = <1>;
			mboxes = <&mailbox>;
			dma-ranges;
			firmware_clocks: clocks {
				compatible = "raspberrypi,firmware-clocks";
				#clock-cells = <1>;
			};
			expgpio: gpio {
				compatible = "raspberrypi,firmware-gpio";
				gpio-controller;
				#gpio-cells = <2>;
				status = "okay";
				gpio-line-names = "BT_ON", "WL_ON", "PWR_LED_OFF", "ANT1", "VDD_SD_IO_SEL", "CAM_GPIO", "SD_PWR_ON", "ANT2";
				ant1: ant1 {
					gpio-hog;
					gpios = <3 GPIO_ACTIVE_HIGH>;
					output-high;
				};
				ant2: ant2 {
					gpio-hog;
					gpios = <7 GPIO_ACTIVE_HIGH>;
					output-low;
				};
			};
			reset: reset {
				compatible = "raspberrypi,firmware-reset";
				#reset-cells = <1>;
			};
			vcio: vcio {
				compatible = "raspberrypi,vcio";
			};
		};
		power: power {
			compatible = "raspberrypi,bcm2835-power";
			firmware = <&firmware>;
			#power-domain-cells = <1>;
		};
		vchiq: mailbox@7e00b840 {
			compatible = "brcm,bcm2711-vchiq";
			reg = <0x7e00b840 0x3c>;
			interrupts = <GIC_SPI 34 IRQ_TYPE_LEVEL_HIGH>;
			pinctrl-names = "default";
			pinctrl-0 = <&audio_pins>;
		};
		gpiomem {
			compatible = "brcm,bcm2835-gpiomem";
			reg = <0x7e200000 0x1000>;
		};
		fb: fb {
			compatible = "brcm,bcm2708-fb";
			firmware = <&firmware>;
			status = "okay";
		};
		sound: sound {
			status = "disabled";
		};
		nvmem {
			compatible = "simple-bus";
			#address-cells = <1>;
			#size-cells = <1>;
			nvmem_otp: nvmem_otp {
				compatible = "raspberrypi,rpi-otp";
				firmware = <&firmware>;
				reg = <0 166>;
				status = "okay";
			};
			nvmem_cust: nvmem_cust {
				compatible = "raspberrypi,rpi-otp";
				firmware = <&firmware>;
				reg = <1 8>;
				status = "okay";
			};
			nvmem_priv: nvmem_priv {
				compatible = "raspberrypi,rpi-otp";
				firmware = <&firmware>;
				reg = <3 8>;
				status = "okay";
			};
		};
	};
	clocks {
		compatible = "simple-bus";
		#address-cells = <1>;
		#size-cells = <0>;
		clk_osc: clk-osc {
			compatible = "fixed-clock";
			#clock-cells = <0>;
			clock-output-names = "osc";
			clock-frequency = <54000000>;
		};
		clk_usb: clk-usb {
			compatible = "fixed-clock";
			#clock-cells = <0>;
			clock-output-names = "otg";
			clock-frequency = <480000000>;
		};
	};
	usbphy: phy {
		compatible = "usb-nop-xceiv";
		#phy-cells = <0>;
	};
	vc4: gpu {
		compatible = "brcm,bcm2711-vc5";
		status = "disabled";
		raspberrypi,firmware = <&firmware>;
	};
	clk_27MHz: clk-27M {
		#clock-cells = <0>;
		compatible = "fixed-clock";
		clock-frequency = <27000000>;
		clock-output-names = "27MHz-clock";
	};
	clk_108MHz: clk-108M {
		#clock-cells = <0>;
		compatible = "fixed-clock";
		clock-frequency = <108000000>;
		clock-output-names = "108MHz-clock";
	};
	emmc2bus: emmc2bus {
		compatible = "simple-bus";
		#address-cells = <2>;
		#size-cells = <1>;
		ranges = <0x0 0x7e000000 0x0 0xfe000000 0x01800000>;
		dma-ranges = <0x0 0xc0000000 0x0 0x00000000 0x40000000>;
		emmc2: mmc@7e340000 {
			compatible = "brcm,bcm2711-emmc2";
			reg = <0x0 0x7e340000 0x100>;
			interrupts = <GIC_SPI 126 IRQ_TYPE_LEVEL_HIGH>;
			clocks = <&clocks BCM2711_CLOCK_EMMC2>;
			status = "okay";
			bus-width = <8>;
			vqmmc-supply = <&sd_io_1v8_reg>;
			vmmc-supply = <&sd_vcc_reg>;
			broken-cd;
			mmc-ddr-3_3v;
		};
	};
	arm-pmu {
		compatible = "arm,cortex-a72-pmu", "arm,armv8-pmuv3", "arm,cortex-a7-pmu";
		interrupts = <GIC_SPI 16 IRQ_TYPE_LEVEL_HIGH>, <GIC_SPI 17 IRQ_TYPE_LEVEL_HIGH>, <GIC_SPI 18 IRQ_TYPE_LEVEL_HIGH>, <GIC_SPI 19 IRQ_TYPE_LEVEL_HIGH>;
		interrupt-affinity = <&cpu0>, <&cpu1>, <&cpu2>, <&cpu3>;
	};
	timer {
		compatible = "arm,armv8-timer";
		interrupts = <GIC_PPI 13 (GIC_CPU_MASK_SIMPLE(4) |IRQ_TYPE_LEVEL_LOW)>, <GIC_PPI 14 (GIC_CPU_MASK_SIMPLE(4) |IRQ_TYPE_LEVEL_LOW)>, <GIC_PPI 11 (GIC_CPU_MASK_SIMPLE(4) |IRQ_TYPE_LEVEL_LOW)>, <GIC_PPI 10 (GIC_CPU_MASK_SIMPLE(4) |IRQ_TYPE_LEVEL_LOW)>;
		arm,cpu-registers-not-fw-configured;
	};
	cpus: cpus {
		#address-cells = <1>;
		#size-cells = <0>;
		enable-method = "brcm,bcm2836-smp";
		cpu0: cpu@0 {
			device_type = "cpu";
			compatible = "arm,cortex-a72";
			reg = <0>;
			enable-method = "spin-table";
			cpu-release-addr = <0x0 0x000000d8>;
			d-cache-size = <0x8000>;
			d-cache-line-size = <64>;
			d-cache-sets = <256>;
			i-cache-size = <0xc000>;
			i-cache-line-size = <64>;
			i-cache-sets = <256>;
			next-level-cache = <&l2>;
		};
		cpu1: cpu@1 {
			device_type = "cpu";
			compatible = "arm,cortex-a72";
			reg = <1>;
			enable-method = "spin-table";
			cpu-release-addr = <0x0 0x000000e0>;
			d-cache-size = <0x8000>;
			d-cache-line-size = <64>;
			d-cache-sets = <256>;
			i-cache-size = <0xc000>;
			i-cache-line-size = <64>;
			i-cache-sets = <256>;
			next-level-cache = <&l2>;
		};
		cpu2: cpu@2 {
			device_type = "cpu";
			compatible = "arm,cortex-a72";
			reg = <2>;
			enable-method = "spin-table";
			cpu-release-addr = <0x0 0x000000e8>;
			d-cache-size = <0x8000>;
			d-cache-line-size = <64>;
			d-cache-sets = <256>;
			i-cache-size = <0xc000>;
			i-cache-line-size = <64>;
			i-cache-sets = <256>;
			next-level-cache = <&l2>;
		};
		cpu3: cpu@3 {
			device_type = "cpu";
			compatible = "arm,cortex-a72";
			reg = <3>;
			enable-method = "spin-table";
			cpu-release-addr = <0x0 0x000000f0>;
			d-cache-size = <0x8000>;
			d-cache-line-size = <64>;
			d-cache-sets = <256>;
			i-cache-size = <0xc000>;
			i-cache-line-size = <64>;
			i-cache-sets = <256>;
			next-level-cache = <&l2>;
		};
		l2: l2-cache0 {
			compatible = "cache";
			cache-unified;
			cache-size = <0x100000>;
			cache-line-size = <64>;
			cache-sets = <1024>;
			cache-level = <2>;
		};
	};
	scb: scb {
		compatible = "simple-bus";
		#address-cells = <2>;
		#size-cells = <2>;
		ranges = <0x0 0x7c000000 0x0 0xfc000000 0x0 0x03800000>, <0x0 0x40000000 0x0 0xff800000 0x0 0x00800000>, <0x6 0x00000000 0x6 0x00000000 0x0 0x80000000>, <0x0 0x00000000 0x0 0x00000000 0x0 0xfc000000>;
		dma-ranges = <0x4 0x7c000000 0x0 0xfc000000 0x0 0x03800000>, <0x0 0x00000000 0x0 0x00000000 0x4 0x00000000>;
		pcie0: pcie@7d500000 {
			compatible = "brcm,bcm2711-pcie";
			reg = <0x0 0x7d500000 0x0 0x9310>;
			device_type = "pci";
			#address-cells = <3>;
			#interrupt-cells = <1>;
			#size-cells = <2>;
			interrupts = <GIC_SPI 147 IRQ_TYPE_LEVEL_HIGH>, <GIC_SPI 148 IRQ_TYPE_LEVEL_HIGH>;
			interrupt-names = "pcie", "msi";
			interrupt-map-mask = <0x0 0x0 0x0 0x7>;
			interrupt-map = <0 0 0 1 &gicv2 GIC_SPI 143 IRQ_TYPE_LEVEL_HIGH>, <0 0 0 2 &gicv2 GIC_SPI 144 IRQ_TYPE_LEVEL_HIGH>, <0 0 0 3 &gicv2 GIC_SPI 145 IRQ_TYPE_LEVEL_HIGH>, <0 0 0 4 &gicv2 GIC_SPI 146 IRQ_TYPE_LEVEL_HIGH>;
			msi-controller;
			msi-parent = <&pcie0>;
			ranges = <0x02000000 0x0 0x80000000 0x6 0x00000000 0x0 0x80000000>;
			dma-ranges = <0x02000000 0x0 0x00000000 0x0 0x00000000 0x0 0xc0000000>;
			brcm,enable-ssc;
			brcm,enable-l1ss;
			pci@0,0 {
				device_type = "pci";
				#address-cells = <3>;
				#size-cells = <2>;
				ranges;
				reg = <0 0 0 0 0>;
			};
		};
		genet: ethernet@7d580000 {
			compatible = "brcm,bcm2711-genet-v5";
			reg = <0x0 0x7d580000 0x0 0x10000>;
			#address-cells = <0x1>;
			#size-cells = <0x1>;
			interrupts = <GIC_SPI 157 IRQ_TYPE_LEVEL_HIGH>, <GIC_SPI 158 IRQ_TYPE_LEVEL_HIGH>;
			status = "okay";
			phy-handle = <&phy1>;
			phy-mode = "rgmii-rxid";
			genet_mdio: mdio@e14 {
				compatible = "brcm,genet-mdio-v5";
				reg = <0xe14 0x8>;
				reg-names = "mdio";
				#address-cells = <0x1>;
				#size-cells = <0x0>;
				phy1: ethernet-phy@0 {
					reg = <0x0>;
					led-modes = <0x00 0x08>;
				};
			};
		};
		dma40: dma@7e007b00 {
			compatible = "brcm,bcm2711-dma";
			reg = <0x0 0x7e007b00 0x0 0x400>;
			interrupts = <GIC_SPI 89 IRQ_TYPE_LEVEL_HIGH>, <GIC_SPI 90 IRQ_TYPE_LEVEL_HIGH>, <GIC_SPI 91 IRQ_TYPE_LEVEL_HIGH>, <GIC_SPI 92 IRQ_TYPE_LEVEL_HIGH>;
			interrupt-names = "dma11", "dma12", "dma13", "dma14";
			#dma-cells = <1>;
			brcm,dma-channel-mask = <0x7000>;
		};
		xhci: xhci@7e9c0000 {
			compatible = "generic-xhci";
			status = "disabled";
			reg = <0x0 0x7e9c0000 0x0 0x100000>;
			interrupts = <GIC_SPI 176 IRQ_TYPE_LEVEL_HIGH>;
			power-domains = <&power RPI_POWER_DOMAIN_USB>;
		};
		codec@7eb10000 {
			compatible = "raspberrypi,rpivid-vid-decoder";
			reg = <0x0 0x7eb10000 0x0 0x1000>, <0x0 0x7eb00000 0x0 0x10000>;
			reg-names = "intc", "hevc";
			interrupts = <GIC_SPI 98 IRQ_TYPE_LEVEL_HIGH>;
			clocks = <&firmware_clocks 11>;
			clock-names = "hevc";
		};
	};
	cam1_reg: cam0_reg: cam1_regulator {
		compatible = "regulator-fixed";
		regulator-name = "cam1-reg";
		enable-active-high;
		status = "okay";
		gpio = <&expgpio 5 GPIO_ACTIVE_HIGH>;
	};
	cam1_clk: cam1_clk {
		compatible = "fixed-clock";
		#clock-cells = <0>;
		status = "disabled";
	};
	cam0_regulator: cam0_regulator {
		compatible = "regulator-fixed";
		regulator-name = "cam0-reg";
		enable-active-high;
		status = "disabled";
	};
	cam0_clk: cam0_clk {
		compatible = "fixed-clock";
		#clock-cells = <0>;
		status = "disabled";
	};
	cam_dummy_reg: cam_dummy_reg {
		compatible = "regulator-fixed";
		regulator-name = "cam-dummy-reg";
		status = "okay";
	};
	__overrides__ {
		cam0-pwdn-ctrl;
		cam0-pwdn;
		cam0-led-ctrl;
		cam0-led;
		bdaddr = <&bt>, "local-bd-address[", <&bt>, "fallback-bd-address?=0", <&minibt>, "local-bd-address[", <&minibt>, "fallback-bd-address?=0";
		krnbt = <&bt>, "status";
		krnbt_baudrate = <&bt>, "max-speed:0", <&minibt>, "max-speed:0";
		cache_line_size;
		uart0 = <&uart0>, "status";
		uart1 = <&uart1>, "status";
		i2s = <&i2s>, "status";
		spi = <&spi0>, "status";
		i2c0 = <&i2c0if>, "status", <&i2c0mux>, "status";
		i2c1 = <&i2c1>, "status";
		i2c = <&i2c1>, "status";
		i2c_arm = <&i2c1>, "status";
		i2c_vc = <&i2c0if>, "status", <&i2c0mux>, "status";
		i2c0_baudrate = <&i2c0if>, "clock-frequency:0";
		i2c1_baudrate = <&i2c1>, "clock-frequency:0";
		i2c_baudrate = <&i2c1>, "clock-frequency:0";
		i2c_arm_baudrate = <&i2c1>, "clock-frequency:0";
		i2c_vc_baudrate = <&i2c0if>, "clock-frequency:0";
		watchdog = <&watchdog>, "status";
		random = <&random>, "status";
		sd_overclock = <&sdhost>, "brcm,overclock-50:0";
		sd_force_pio = <&sdhost>, "brcm,force-pio?";
		sd_pio_limit = <&sdhost>, "brcm,pio-limit:0";
		sd_debug = <&sdhost>, "brcm,debug";
		sdio_overclock = <&mmc>, "brcm,overclock-50:0", <&mmcnr>, "brcm,overclock-50:0";
		axiperf = <&axiperf>, "status";
		drm_fb0_vc4 = <&aliases>, "drm-fb0=", &vc4;
		drm_fb1_vc4 = <&aliases>, "drm-fb1=", &vc4;
		drm_fb2_vc4 = <&aliases>, "drm-fb2=", &vc4;
		cam1_sync = <&csi1>, "sync-gpios:0=", <&gpio>, <&csi1>, "sync-gpios:4", <&csi1>, "sync-gpios:8=", <GPIO_ACTIVE_HIGH>;
		cam1_sync_inverted = <&csi1>, "sync-gpios:0=", <&gpio>, <&csi1>, "sync-gpios:4", <&csi1>, "sync-gpios:8=", <GPIO_ACTIVE_LOW>;
		cam0_sync = <&csi0>, "sync-gpios:0=", <&gpio>, <&csi0>, "sync-gpios:4", <&csi0>, "sync-gpios:8=", <GPIO_ACTIVE_HIGH>;
		cam0_sync_inverted = <&csi0>, "sync-gpios:0=", <&gpio>, <&csi0>, "sync-gpios:4", <&csi0>, "sync-gpios:8=", <GPIO_ACTIVE_LOW>;
		cam0_reg = <&cam0_reg>, "status";
		cam0_reg_gpio = <&cam0_reg>, "gpio:4", <&cam0_reg>, "gpio:0=", <&gpio>;
		cam1_reg = <&cam1_reg>, "status";
		cam1_reg_gpio = <&cam1_reg>, "gpio:4", <&cam1_reg>, "gpio:0=", <&gpio>;
		strict_gpiod = <&chosen>, "bootargs=pinctrl_bcm2835.persist_gpio_outputs=n";
		arm_freq;
		eee = <&chosen>, "bootargs{on='',off='genet.eee=N'}";
		hdmi = <&hdmi0>, "status", <&hdmi1>, "status";
		nvmem_cust_rw = <&nvmem_cust>, "rw?";
		nvmem_priv_rw = <&nvmem_priv>, "rw?";
		pcie = <&pcie0>, "status";
		sd = <&emmc2>, "status";
		sd_poll_once = <&emmc2>, "non-removable?";
		spi_dma4 = <&spi0>, "dmas:0=", <&dma40>, <&spi0>, "dmas:8=", <&dma40>;
		i2s_dma4 = <&i2s>, "dmas:0=", <&dma40>, <&i2s>, "dmas:8=", <&dma40>;
		audio = <&chosen>, "bootargs{on='snd_bcm2835.enable_hdmi=1',off='snd_bcm2835.enable_hdmi=0'}";
		act_led_gpio = <&led_act>, "gpios:4";
		act_led_activelow = <&led_act>, "gpios:8";
		act_led_trigger = <&led_act>, "linux,default-trigger";
		pwr_led_gpio = <&led_pwr>, "gpios:4";
		pwr_led_activelow = <&led_pwr>, "gpios:8";
		pwr_led_trigger = <&led_pwr>, "linux,default-trigger";
		eth_led0 = <&phy1>, "led-modes:0";
		eth_led1 = <&phy1>, "led-modes:4";
		ant1 = <&ant1>, "output-high?=on", <&ant1>, "output-low?=off", <&ant2>, "output-high?=off", <&ant2>, "output-low?=on";
		ant2 = <&ant1>, "output-high?=off", <&ant1>, "output-low?=on", <&ant2>, "output-high?=on", <&ant2>, "output-low?=off";
		noant = <&ant1>, "output-high?=off", <&ant1>, "output-low?=on", <&ant2>, "output-high?=off", <&ant2>, "output-low?=on";
		pcie_tperst_clk_ms = <&pcie0>, "brcm,tperst-clk-ms:0";
	};
	memory@0 {
		device_type = "memory";
		reg = <0 0 0>;
	};
	leds: leds {
		compatible = "gpio-leds";
		led_act: led-act {
			label = "ACT";
			default-state = "off";
			linux,default-trigger = "mmc0";
			gpios = <&gpio 42 GPIO_ACTIVE_HIGH>;
		};
		led_pwr: led-pwr {
			label = "PWR";
			gpios = <&expgpio 2 GPIO_ACTIVE_LOW>;
			default-state = "off";
			linux,default-trigger = "default-on";
		};
	};
	sd_io_1v8_reg: sd_io_1v8_reg {
		compatible = "regulator-gpio";
		regulator-name = "vdd-sd-io";
		regulator-min-microvolt = <1800000>;
		regulator-max-microvolt = <3300000>;
		regulator-boot-on;
		regulator-always-on;
		regulator-settling-time-us = <5000>;
		gpios = <&expgpio 4 GPIO_ACTIVE_HIGH>;
		states = <1800000 0x1>, <3300000 0x0>;
		status = "okay";
	};
	sd_vcc_reg: sd_vcc_reg {
		compatible = "regulator-fixed";
		regulator-name = "vcc-sd";
		regulator-min-microvolt = <3300000>;
		regulator-max-microvolt = <3300000>;
		regulator-boot-on;
		enable-active-high;
		gpio = <&expgpio 6 GPIO_ACTIVE_HIGH>;
	};
	vdd_3v3_reg: fixedregulator_3v3 {
		compatible = "regulator-fixed";
		regulator-always-on;
		regulator-max-microvolt = <3300000>;
		regulator-min-microvolt = <3300000>;
		regulator-name = "3v3";
	};
	vdd_5v0_reg: fixedregulator_5v0 {
		compatible = "regulator-fixed";
		regulator-always-on;
		regulator-max-microvolt = <5000000>;
		regulator-min-microvolt = <5000000>;
		regulator-name = "5v0";
	};
	zone_dma {
		#address-cells = <1>;
		#size-cells = <1>;
		dma-ranges = <0x0 0x0 0x0 0x40000000>;
	};
	v3dbus: v3dbus {
		compatible = "simple-bus";
		#address-cells = <1>;
		#size-cells = <2>;
		ranges = <0x7c500000 0x0 0xfc500000 0x0 0x03300000>, <0x40000000 0x0 0xff800000 0x0 0x00800000>;
		dma-ranges = <0x00000000 0x0 0x00000000 0x4 0x00000000>;
		v3d: v3d@7ec04000 {
			compatible = "brcm,2711-v3d";
			reg = <0x7ec00000 0x0 0x4000>, <0x7ec04000 0x0 0x4000>;
			reg-names = "hub", "core0";
			power-domains = <&pm BCM2835_POWER_DOMAIN_GRAFX_V3D>;
			resets = <&pm BCM2835_RESET_V3D>;
			clocks = <&firmware_clocks 5>;
			clocks-names = "v3d";
			interrupts = <GIC_SPI 74 IRQ_TYPE_LEVEL_HIGH>;
			status = "disabled";
		};
	};
};
